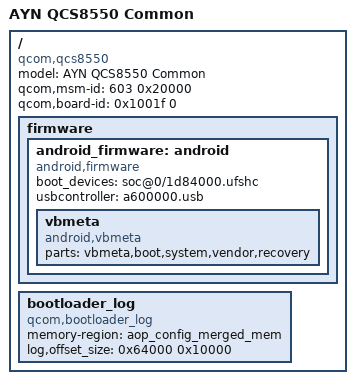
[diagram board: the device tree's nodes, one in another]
// SPDX-License-Identifier: BSD-3-Clause
// SPDX-FileCopyrightText: The LineageOS Project

/dts-v1/;

#include "qcs8550-ayn-common.dtsi"

/ {
	model = "AYN QCS8550 Common";
	compatible = "qcom,qcs8550", "qcom,sm8550";
	qcom,msm-id = <603 0x20000>;
	qcom,board-id = <0x1001f 0>;

	firmware {
		android_firmware: android {
			compatible = "android,firmware";
			boot_devices = "soc@0/1d84000.ufshc";
			usbcontroller = "a600000.usb";

			vbmeta {
				compatible = "android,vbmeta";
				parts = "vbmeta,boot,system,vendor,recovery";
			};
		};
	};

	bootloader_log {
		compatible = "qcom,bootloader_log";
		memory-region = <&aop_config_merged_mem>;
		log,offset_size = <0x64000 0x10000>;
	};
};
